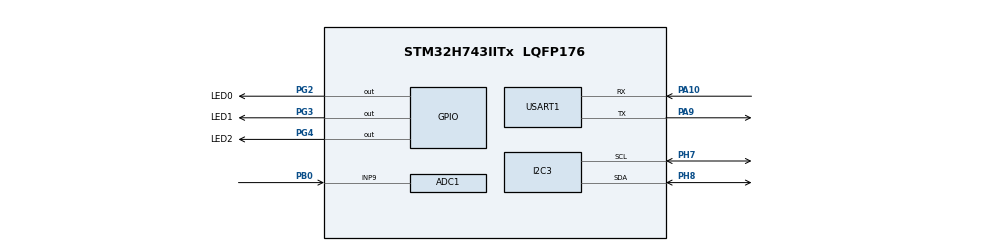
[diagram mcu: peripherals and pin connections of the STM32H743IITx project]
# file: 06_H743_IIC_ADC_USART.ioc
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ADC1.Channel-0\#ChannelRegularConversion=ADC_CHANNEL_9
ADC1.NbrOfConversionFlag=1
ADC1.OffsetNumber-0\#ChannelRegularConversion=ADC_OFFSET_NONE
ADC1.Rank-0\#ChannelRegularConversion=1
ADC1.SamplingTime-0\#ChannelRegularConversion=ADC_SAMPLETIME_1CYCLE_5
ADC1.master=1
I2C3.Timing=0x10C0ECFF
Mcu.Family=STM32H7
Mcu.Name=STM32H743IITx
Mcu.Package=LQFP176
NVIC.PriorityGroup=NVIC_PRIORITYGROUP_4
PA10.Mode=Asynchronous
PA10.Signal=USART1_RX
PA9.Mode=Asynchronous
PA9.Signal=USART1_TX
PB0.Signal=ADCx_INP9
PC14-OSC32_IN\ (OSC32_IN).Mode=LSE-External-Oscillator
PC14-OSC32_IN\ (OSC32_IN).Signal=RCC_OSC32_IN
PC15-OSC32_OUT\ (OSC32_OUT).Mode=LSE-External-Oscillator
PC15-OSC32_OUT\ (OSC32_OUT).Signal=RCC_OSC32_OUT
PG2.GPIO_Label=LED0
PG2.Signal=GPIO_Output
PG3.GPIO_Label=LED1
PG3.Signal=GPIO_Output
PG4.GPIO_Label=LED2
PG4.Signal=GPIO_Output
PH0-OSC_IN\ (PH0).Mode=HSE-External-Oscillator
PH0-OSC_IN\ (PH0).Signal=RCC_OSC_IN
PH1-OSC_OUT\ (PH1).Mode=HSE-External-Oscillator
PH1-OSC_OUT\ (PH1).Signal=RCC_OSC_OUT
PH7.Mode=I2C
PH7.Signal=I2C3_SCL
PH8.Mode=I2C
PH8.Signal=I2C3_SDA
ProjectManager.HeapSize=0x200
ProjectManager.StackSize=0x400
ProjectManager.TargetToolchain=STM32CubeIDE
RCC.ADCFreq_Value=75000000
RCC.APB1Freq_Value=100000000
RCC.APB2Freq_Value=100000000
RCC.APB3Freq_Value=100000000
RCC.APB4Freq_Value=100000000
RCC.CortexFreq_Value=400000000
RCC.D1PPRE=RCC_APB3_DIV2
RCC.D2PPRE1=RCC_APB1_DIV2
RCC.D2PPRE2=RCC_APB2_DIV2
RCC.D3PPRE=RCC_APB4_DIV2
RCC.DIVM1=5
RCC.DIVM2=2
RCC.DIVN1=160
RCC.DIVN2=12
RCC.HCLKFreq_Value=200000000
RCC.HPRE=RCC_HCLK_DIV2
RCC.PLL2FRACN=0
RCC.PLL3FRACN=0
RCC.PLLFRACN=0
RCC.PLLSourceVirtual=RCC_PLLSOURCE_HSE
RCC.SYSCLKFreq_VALUE=400000000
RCC.SYSCLKSource=RCC_SYSCLKSOURCE_PLLCLK
RCC.USBFreq_Value=400000000
SH.ADCx_INP9.0=ADC1_INP9,IN9-Single-Ended
USART1.VirtualMode-Asynchronous=VM_ASYNC
board=custom

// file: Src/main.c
/* USER CODE BEGIN Header */
/**
 ******************************************************************************
 * @file           : main.c
 * @brief          : Main program body
 ******************************************************************************
 * @attention
 *
 * <h2><center>&copy; Copyright (c) 2020 STMicroelectronics.
 * All rights reserved.</center></h2>
 *
 * This software component is licensed by ST under BSD 3-Clause license,
 * the "License"; You may not use this file except in compliance with the
 * License. You may obtain a copy of the License at:
 *                        opensource.org/licenses/BSD-3-Clause
 *
 ******************************************************************************
 */
/* USER CODE END Header */

#include "main.h"
#include "adc.h"
#include "i2c.h"
#include "usart.h"
#include "gpio.h"

/* USER CODE BEGIN PD */
#define HDC1080_ADDRESS         0x40 << 1
#define HDC1080_TEMPERATURE     0x00
#define HDC1080_HUMIDITY        0X01
/* USER CODE END PD */

/* USER CODE BEGIN PV */
uint32_t main_loop = 0;
uint8_t hdc1080_write_buffer[2];
uint16_t Read_Humidity,Read_Temperature;
/* USER CODE END PV */

void SystemClock_Config(void);

int main(void)
{

    /* MCU Configuration--------------------------------------------------------*/

    /* Reset of all peripherals, Initializes the Flash interface and the Systick. */
    HAL_Init();

    /* Configure the system clock */
    SystemClock_Config();

    /* Initialize all configured peripherals */
    MX_GPIO_Init();
    MX_ADC1_Init();
    MX_I2C3_Init();
    MX_USART1_UART_Init();

    /* Infinite loop */
    while (1) {
        hdc1080_write_buffer[0] = HDC1080_TEMPERATURE;
        HAL_I2C_Master_Transmit(&hi2c3, HDC1080_ADDRESS, hdc1080_write_buffer, 1, 100);
        HAL_Delay(20);
        HAL_I2C_Master_Receive(&hi2c3,HDC1080_ADDRESS,hdc1080_write_buffer,2,100);
        Read_Temperature = hdc1080_write_buffer[0] << 8 | hdc1080_write_buffer[1];
        printf("HDC1080_Temperature is : 0x%x\r\n", Read_Temperature);
        HAL_GPIO_TogglePin(GPIOG, LED0_Pin|LED1_Pin|LED2_Pin);
        printf("System main_loop is : %d\r\n", main_loop);
        main_loop++;
        HAL_Delay(1000);

    }
}

void SystemClock_Config(void) {
	RCC_OscInitTypeDef RCC_OscInitStruct = { 0 };
	RCC_ClkInitTypeDef RCC_ClkInitStruct = { 0 };
	RCC_PeriphCLKInitTypeDef PeriphClkInitStruct = { 0 };

	/** Supply configuration update enable
	 */
	HAL_PWREx_ConfigSupply(PWR_LDO_SUPPLY);
	/** Configure the main internal regulator output voltage
	 */
	__HAL_PWR_VOLTAGESCALING_CONFIG(PWR_REGULATOR_VOLTAGE_SCALE1);

	while (!__HAL_PWR_GET_FLAG(PWR_FLAG_VOSRDY)) {
	}
	/** Macro to configure the PLL clock source
	 */
	__HAL_RCC_PLL_PLLSOURCE_CONFIG(RCC_PLLSOURCE_HSE);
	/** Initializes the CPU, AHB and APB busses clocks
	 */
	RCC_OscInitStruct.OscillatorType = RCC_OSCILLATORTYPE_HSE;
	RCC_OscInitStruct.HSEState = RCC_HSE_ON;
	RCC_OscInitStruct.PLL.PLLState = RCC_PLL_ON;
	RCC_OscInitStruct.PLL.PLLSource = RCC_PLLSOURCE_HSE;
	RCC_OscInitStruct.PLL.PLLM = 5;
	RCC_OscInitStruct.PLL.PLLN = 160;
	RCC_OscInitStruct.PLL.PLLP = 2;
	RCC_OscInitStruct.PLL.PLLQ = 2;
	RCC_OscInitStruct.PLL.PLLR = 2;
	RCC_OscInitStruct.PLL.PLLRGE = RCC_PLL1VCIRANGE_2;
	RCC_OscInitStruct.PLL.PLLVCOSEL = RCC_PLL1VCOWIDE;
	RCC_OscInitStruct.PLL.PLLFRACN = 0;
	if (HAL_RCC_OscConfig(&RCC_OscInitStruct) != HAL_OK) {
		Error_Handler();
	}
	/** Initializes the CPU, AHB and APB busses clocks
	 */
	RCC_ClkInitStruct.ClockType = RCC_CLOCKTYPE_HCLK | RCC_CLOCKTYPE_SYSCLK
			| RCC_CLOCKTYPE_PCLK1 | RCC_CLOCKTYPE_PCLK2 | RCC_CLOCKTYPE_D3PCLK1
			| RCC_CLOCKTYPE_D1PCLK1;
	RCC_ClkInitStruct.SYSCLKSource = RCC_SYSCLKSOURCE_PLLCLK;
	RCC_ClkInitStruct.SYSCLKDivider = RCC_SYSCLK_DIV1;
	RCC_ClkInitStruct.AHBCLKDivider = RCC_HCLK_DIV2;
	RCC_ClkInitStruct.APB3CLKDivider = RCC_APB3_DIV2;
	RCC_ClkInitStruct.APB1CLKDivider = RCC_APB1_DIV2;
	RCC_ClkInitStruct.APB2CLKDivider = RCC_APB2_DIV2;
	RCC_ClkInitStruct.APB4CLKDivider = RCC_APB4_DIV2;

	if (HAL_RCC_ClockConfig(&RCC_ClkInitStruct, FLASH_LATENCY_2) != HAL_OK) {
		Error_Handler();
	}
	PeriphClkInitStruct.PeriphClockSelection = RCC_PERIPHCLK_USART1
			| RCC_PERIPHCLK_I2C3 | RCC_PERIPHCLK_ADC;
	PeriphClkInitStruct.PLL2.PLL2M = 2;
	PeriphClkInitStruct.PLL2.PLL2N = 12;
	PeriphClkInitStruct.PLL2.PLL2P = 2;
	PeriphClkInitStruct.PLL2.PLL2Q = 2;
	PeriphClkInitStruct.PLL2.PLL2R = 2;
	PeriphClkInitStruct.PLL2.PLL2RGE = RCC_PLL2VCIRANGE_3;
	PeriphClkInitStruct.PLL2.PLL2VCOSEL = RCC_PLL2VCOMEDIUM;
	PeriphClkInitStruct.PLL2.PLL2FRACN = 0;
	PeriphClkInitStruct.Usart16ClockSelection = RCC_USART16CLKSOURCE_D2PCLK2;
	PeriphClkInitStruct.I2c123ClockSelection = RCC_I2C123CLKSOURCE_D2PCLK1;
	PeriphClkInitStruct.AdcClockSelection = RCC_ADCCLKSOURCE_PLL2;
	if (HAL_RCCEx_PeriphCLKConfig(&PeriphClkInitStruct) != HAL_OK) {
		Error_Handler();
	}
}

void Error_Handler(void) {
}

/************************ (C) COPYRIGHT STMicroelectronics *****END OF FILE****/
